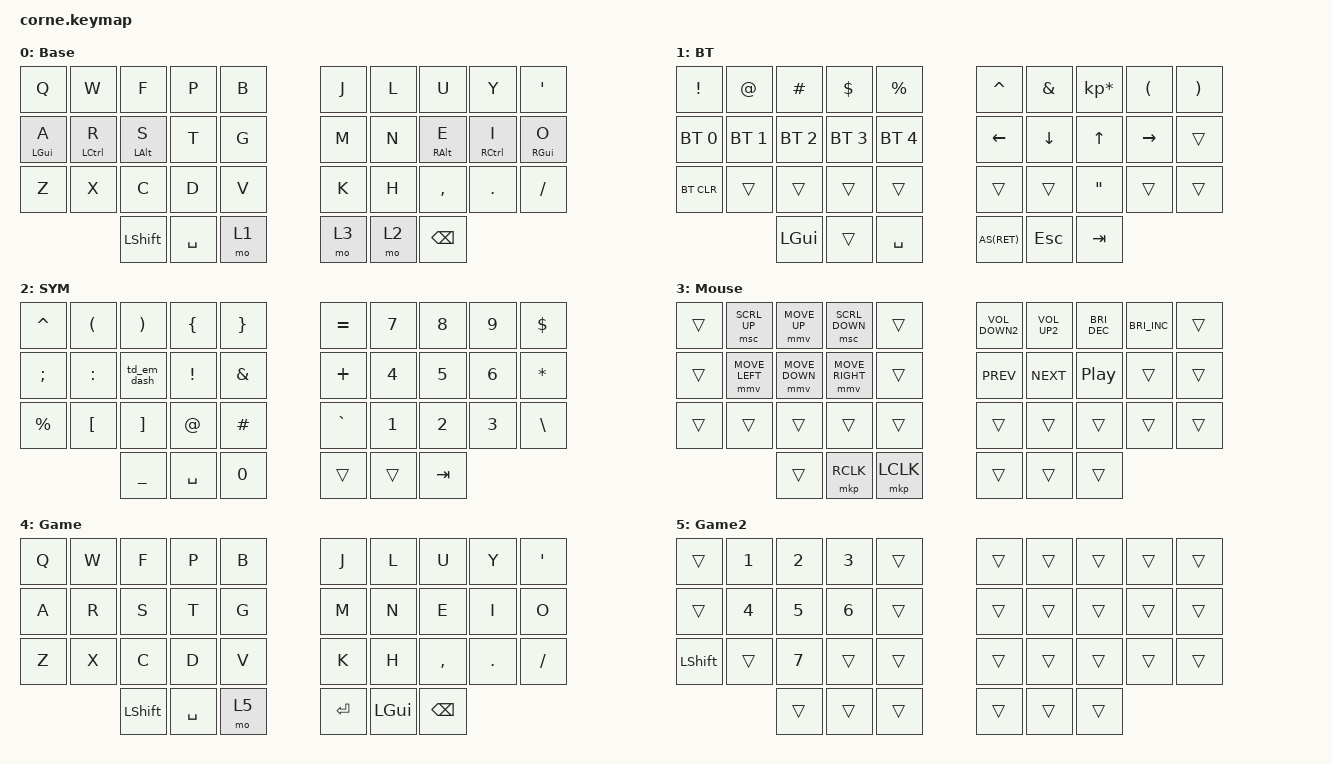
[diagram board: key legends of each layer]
/*
 * Copyright (c) 2020 The ZMK Contributors
 *
 * SPDX-License-Identifier: MIT
 */

#include <behaviors.dtsi>
#include <dt-bindings/zmk/keys.h>
#include <dt-bindings/zmk/bt.h>
#include <dt-bindings/zmk/pointing.h>

#define ZMK_POINTING_DEFAULT_MOVE_VAL 1500  // default is 600
#define ZMK_POINTING_DEFAULT_SCRL_VAL 15    // default is 10

#define AS(keycode) &as LS(keycode) keycode

/ {

    combos {
        compatible = "zmk,combos";

        enter-combo {
            bindings = <&kp ENTER>;
            key-positions = <16 17 18>;
        };

        esc-combo {
            bindings = <&kp ESCAPE>;
            key-positions = <0 1>;
        };

        game-layer {
            bindings = <&to 4>;
            key-positions = <6 7 8>;
            layers = <0>;
        };

        disable-game-layer {
            bindings = <&to 0>;
            key-positions = <26 27 28>;
            layers = <4>;
        };

        copy {
            bindings = <&kp K_COPY>;
            key-positions = <21 22>;
            layers = <0>;
        };

        paste {
            bindings = <&kp K_PASTE>;
            key-positions = <21 23>;
            layers = <0>;
        };
    };

    macros {
        td_dash: td_dash {
            label = "TD_DASH";
            compatible = "zmk,behavior-macro";
            #binding-cells = <0>;
            tap-ms = <0>;
            wait-ms = <0>;
            bindings = 
                /* Double-tap path */
                <&macro_press   &kp LCTRL &kp LSHIFT>,
                <&macro_tap     &kp U>,
                <&macro_release &kp LCTRL &kp LSHIFT>,
                <&macro_tap     &kp N2 &kp N0 &kp N1 &kp N4 &kp SPC>
                /* On tap only minus, we fall back to a separate binding in keymap */
            ;
        };
    };

    chosen {
        zmk,physical-layout = &foostan_corne_5col_layout;
    };

    behaviors {
        as: auto_shift {
            compatible = "zmk,behavior-hold-tap";
            #binding-cells = <2>;
            tapping_term_ms = <200>;
            quick_tap_ms = <0>;
            flavor = "tap-preferred";
            bindings = <&kp>, <&kp>;
        };
        f_mt: f_mt {
            compatible = "zmk,behavior-hold-tap";
            label = "F_MT";
            bindings = <&kp>, <&kp>;
            flavor = "tap-preferred";
            #binding-cells = <2>;
            tapping-term-ms = <200>; // 200 for now instead of 150ms because I am still getting used to the layout.
        };
        l_mt: l_mt {
            compatible = "zmk,behavior-hold-tap";
            label = "L_MT";
            bindings = <&kp>, <&kp>;
            flavor = "tap-preferred";
            #binding-cells = <2>;
            tapping-term-ms = <300>;
        };
        td_em_dash: tap_dance_dash {
            compatible = "zmk,behavior-tap-dance";
            #binding-cells = <0>;
            tapping-term-ms = <200>;
            bindings = <&kp MINUS>, <&td_dash>;
        };
    };
        keymap {
                compatible = "zmk,keymap";

                default_layer {
// -----------------------------------------------------------------------------------------
// |  Q  |  W  |  F  |  P  |  B  |     |  J  |  L   |  U   |  Y   | ' |
// |  A  |  R  |  S  |  T  |  G  |     |  M  |  N   |  E   |  I   | O | 
// |  Z  |  X  |  C  |  D  |  V  |     |  K  |  H   | , | . | / |
//             | SHFT| SPC | LWR |     | LY3 | RSE  | BSPC |



                        display-name = "Base";
                        bindings = <
                               //AS(Q) AS(W) AS(F) AS(P) AS(B)     AS(J)   AS(L)  AS(U)     AS(Y)     AS(APOS)
                               //AS(A) AS(R) AS(S) AS(T) AS(G)     AS(M)   AS(N)  AS(E)     AS(I)     AS(O)
                               //AS(Z) AS(X) AS(C) AS(D) AS(V)     AS(K)   AS(H)  AS(COMMA) AS(DOT)   AS(FSLH)
                               //probably could be deleted since I found a better setup. I might come back to this though.
    &kp Q   &kp W   &kp F   &kp P   &kp B         &kp J   &kp L    &kp U   &kp Y   &kp APOS
    &f_mt LGUI A   &f_mt LCTRL R   &l_mt LALT S   &kp T   &kp G         &kp M   &kp N    &l_mt RALT E &f_mt RCTRL I &f_mt RGUI O
    &kp Z   &kp X   &kp C   &kp D   &kp V         &kp K   &kp H    &kp COMMA   &kp DOT   &kp FSLH
           &kp LSHFT &kp SPACE &mo 1         &mo 3   &mo 2  &kp BSPC
                        >;
                };

                lower_layer {
// | !     |  @  |  #  |  $  |  %  |     |  ^  |  &  |  *  |  (  |  )  |
// | BT1   | BT2 | BT3 | BT4 | BT5 |     | LFT | DWN |  UP | RGT |     |
// | BTCLR |     |     |     |     |     |     |     |     |     |     |
//               | GUI |     | SPC |     | ENT | ESC | TAB |
                        display-name = "BT";
                        bindings = <
   &kp EXCL     &kp AT       &kp HASH     &kp DLLR     &kp PRCNT        &kp CARET &kp AMPS  &kp KP_MULTIPLY &kp LPAR  &kp RPAR
   &bt BT_SEL 0 &bt BT_SEL 1 &bt BT_SEL 2 &bt BT_SEL 3 &bt BT_SEL 4     &kp LEFT  &kp DOWN  &kp UP          &kp RIGHT &trans 
   &bt BT_CLR   &trans       &trans       &trans       &trans           &trans    &trans    &kp DOUBLE_QUOTES &trans    &trans 
                             &kp LGUI     &trans       &kp SPACE        AS(RET)   &kp ESC   &kp TAB
                        >;
                };

                raise_layer {
// -----------------------------------------------------------------------------------------
                            // | 1! |  2@ |  3# |  4$ |  5% |     |  6^ |  7& |  8* |  9(  |  0)  |
                            // | -_ |  =+ |  {  |  [  |  (  |     |  )  |  ]  |  }  |  /?  |  \|  |
                            // | `~ |     |     |  ,< |  :  |     |  ;  |  .> | CTRL| META |      |
                            //            | GUI | ESC | SPC |     | ENT |     | TAB |
                           //AS(N1)    AS(N2)    AS(N3)    AS(N4)    AS(N5)        AS(N6)    AS(N7)    AS(N8)    AS(N9)   AS(N0)
                           //AS(MINUS) AS(EQUAL) &kp LBRC  &kp LBKT  &kp LPAR      &kp RPAR  &kp RBKT  &kp RBRC  AS(FSLH) AS(BSLH)
                           //AS(GRAVE) &trans    &trans    AS(COMMA) &kp COLON     &kp SEMI  AS(DOT)   &kp LCTRL &kp RALT &trans

                            //old keybinds


//|  ^  |  (  |  )  |  {  |  }  |     |  =  |  7  |  8  |  9  |  $  |
//|  ;  |  :  |  -  |  !  |  &  |     |  +  |  4  |  5  |  6  |  *  |
//|  %  |  [  |  ]  |  @  |  #  |     |  `  |  1  |  2  |  3  |  \| |
//            |  "  | SPC |  0  |     | TRNS | TRNS | TAB |

                        display-name = "SYM";
                        bindings = <



    &kp CARET   &kp LEFT_PARENTHESIS  &kp RIGHT_PARENTHESIS  &kp LEFT_BRACE  &kp RIGHT_BRACE    &kp EQUAL  &kp NUMBER_7  &kp N8        &kp NUMBER_9  &kp DOLLAR
    &kp SEMI    &kp COLON             &td_em_dash            &kp EXCL        &kp AMPERSAND      &kp PLUS   &kp NUMBER_4  &kp N5        &kp NUMBER_6  &kp ASTRK
    &kp PERCENT &kp LEFT_BRACKET      &kp RIGHT_BRACKET      &kp AT          &kp HASH           &kp GRAVE  &kp NUMBER_1  &kp NUMBER_2  &kp NUMBER_3  &kp BACKSLASH
                       &kp UNDER      &kp SPACE     &kp N0          &trans     &trans        &kp TAB
                        >;
                };

                mouse_layer {
                        display-name = "Mouse";
                        bindings = <

   &trans   &msc SCRL_UP   &mmv MOVE_UP   &msc SCRL_DOWN  &trans          &kp K_VOLUME_DOWN2 &kp K_VOLUME_UP2 &kp C_BRIGHTNESS_DEC &kp C_BRIGHTNESS_INC    &trans 
   &trans   &mmv MOVE_LEFT &mmv MOVE_DOWN &mmv MOVE_RIGHT &trans          &kp C_PREV &kp C_NEXT &kp C_PLAY_PAUSE   &trans    &trans
   &trans   &trans         &trans         &trans          &trans          &trans    &trans    &trans      &trans    &trans
                           &trans         &mkp RCLK       &mkp LCLK       &trans    &trans    &trans
                        >;
                };

                game_layer {
// -----------------------------------------------------------------------------------------
// | Q | W | F | P | B |     | J | L | U | Y | ' |
// | A | R | S | T | G |     | M | N | E | I | O | 
// | Z | X | C | D | V |     | K | H | , | . | / |
// | CTRL | SHFT | SPC |     | ENT | GUI | BKSP |
                        display-name = "Game";
                        bindings = <

    &kp Q   &kp W   &kp F   &kp P   &kp B               &kp J   &kp L    &kp U   &kp Y   &kp APOS
    &kp A   &kp R   &kp S   &kp T   &kp G               &kp M   &kp N    &kp E   &kp I   &kp O
    &kp Z   &kp X   &kp C   &kp D   &kp V               &kp K   &kp H    &kp COMMA   &kp DOT   &kp FSLH
            &kp LSHFT &kp SPACE     &mo 5               &kp RET &kp LGUI &kp BSPC
                        >;
                };

                game_layer_2 {
// -----------------------------------------------------------------------------------------
// |   | 1 | 2 | 3 |   |     | J | L | U | Y | ' |
// |   | 4 | 5 | 6 |   |     | M | N | E | I | O | 
// |   |   | 7 |   |   |     | K | H | , | . | / |
// | CTRL | SHFT | SPC |     | ENT | GUI | BKSP |
                        display-name = "Game2";
                        bindings = <

    &trans   &kp N1     &kp N2     &kp N3    &trans          &trans    &trans    &trans      &trans    &trans
    &trans   &kp N4     &kp N5     &kp N6    &trans          &trans    &trans    &trans      &trans    &trans
    &kp LSHFT &trans    &kp N7     &trans    &trans          &trans    &trans    &trans      &trans    &trans
                        &trans     &trans    &trans          &trans    &trans    &trans
                        >;
                };

                extra_1 {
                        status = "reserved";
                };

                extra_2 {
                        status = "reserved";
                };

                extra_3 {
                        status = "reserved";
                };
        };
};
